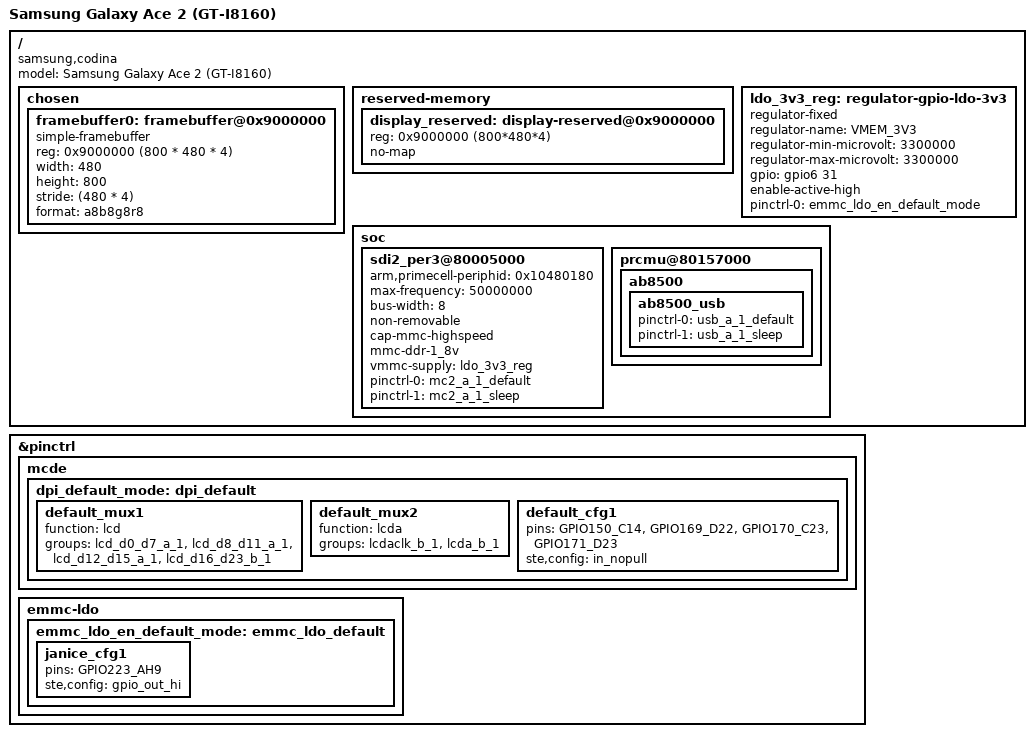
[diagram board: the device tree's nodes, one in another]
/dts-v1/;
#include "ste-db8500.dtsi"
#include "ste-ab8500.dtsi"
#include "ste-dbx5x0-pinctrl.dtsi"
#include <dt-bindings/gpio/gpio.h>
#include <dt-bindings/input/input.h>
#include <dt-bindings/interrupt-controller/irq.h>

/ {
	model = "Samsung Galaxy Ace 2 (GT-I8160)";
	compatible = "samsung,codina", "st-ericsson,u8500";

    chosen {
		#address-cells = <0x1>;
		#size-cells = <0x1>;
		ranges;
	    framebuffer0: framebuffer@0x9000000 {
		    compatible = "simple-framebuffer";
		    reg = <0x9000000 (800 * 480 * 4)>;
		    width = <480>;
		    height = <800>;
		    stride = <(480 * 4)>;
		    format = "a8b8g8r8";
            status = "okay";
        };
    };
    reserved-memory {
		#address-cells = <1>;
		#size-cells = <1>;
		ranges;
        display_reserved: display-reserved@0x9000000 {
			reg = <0x9000000 (800*480*4)>;
			no-map;
		};
    };

	/* External LDO for eMMC LDO VMEM_3V3 controlled by GPIO6 */
	ldo_3v3_reg: regulator-gpio-ldo-3v3 {
		compatible = "regulator-fixed";
		/* Supplied in turn by VBAT */
		regulator-name = "VMEM_3V3";
		regulator-min-microvolt = <3300000>;
		regulator-max-microvolt = <3300000>;
		gpio = <&gpio6 31 GPIO_ACTIVE_HIGH>;
		enable-active-high;
		pinctrl-names = "default";
		pinctrl-0 = <&emmc_ldo_en_default_mode>;
	};

	soc{
		/* eMMC */
		sdi2_per3@80005000 {
			arm,primecell-periphid = <0x10480180>;
		    max-frequency = <50000000>;
			bus-width = <8>;
			non-removable;
			cap-mmc-highspeed;
			mmc-ddr-1_8v;
			vmmc-supply = <&ldo_3v3_reg>;
			pinctrl-names = "default", "sleep";
			pinctrl-0 = <&mc2_a_1_default>;
			pinctrl-1 = <&mc2_a_1_sleep>;
			status = "okay";
		};
		prcmu@80157000 {
			ab8500 {
				ab8500_usb {
					pinctrl-names = "default", "sleep";
					pinctrl-0 = <&usb_a_1_default>;
					pinctrl-1 = <&usb_a_1_sleep>;
				};
			};
		};
	};
};


&pinctrl {
	/*
	 * This extends the MC0_A_2 default config to include
	 * the card detect GPIO217 line.
	 */
	mcde {
		dpi_default_mode: dpi_default {
			default_mux1 {
				/* Mux in all the data lines */
				function = "lcd";
				groups =
					/* Data lines D0-D7 GPIO70..GPIO77 */
					"lcd_d0_d7_a_1",
					/* Data lines D8-D11 GPIO78..GPIO81 */
					"lcd_d8_d11_a_1",
					/* Data lines D12-D15 GPIO82..GPIO85 */
					"lcd_d12_d15_a_1",
					/* Data lines D16-D23 GPIO161..GPIO168 */
					"lcd_d16_d23_b_1";
			};
			default_mux2 {
				function = "lcda";
				/* Clock line on GPIO150, DE, VSO, HSO on GPIO169..GPIO171 */
				groups = "lcdaclk_b_1", "lcda_b_1";
			};
			/* Input, no pull-up is the default state for pins used for an alt function */
			default_cfg1 {
				pins = "GPIO150_C14", "GPIO169_D22", "GPIO170_C23", "GPIO171_D23";
				ste,config = <&in_nopull>;
			};
		};
	};
	/* GPIO that enables the LDO regulator for the eMMC */
	emmc-ldo {
		emmc_ldo_en_default_mode: emmc_ldo_default {
			/* LDO enable on GPIO223 */
			janice_cfg1 {
				pins = "GPIO223_AH9";
				ste,config = <&gpio_out_hi>;
			};
		};
	};
};
